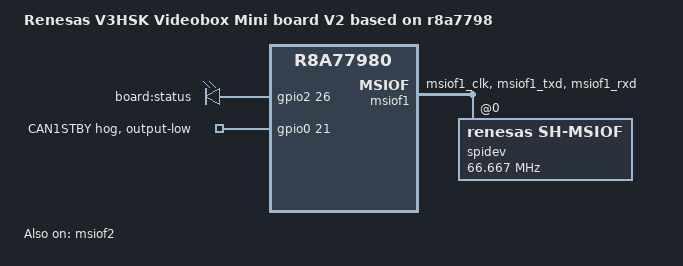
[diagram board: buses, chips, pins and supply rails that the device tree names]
/*
 * Device Tree Source for the V3HSK Videobox Mini board V2 on r8a7798
 *
 * Copyright (C) 2018 Cogent Embedded, Inc.
 *
 * This file is licensed under the terms of the GNU General Public License
 * version 2.  This program is licensed "as is" without any warranty of any
 * kind, whether express or implied.
 */

#include "r8a7798-v3hsk-vbm.dts"

/ {
	model = "Renesas V3HSK Videobox Mini board V2 based on r8a7798";

	leds {
		compatible = "gpio-leds";

		led5 {
			label = "board:status";
			gpios = <&gpio2 26 GPIO_ACTIVE_HIGH>;
			linux,default-trigger = "heartbeat";
		};
	};
};

&gpio0 {
	can1_stby {
		gpio-hog;
		gpios = <21 GPIO_ACTIVE_HIGH>;
		output-low;
		line-name = "CAN1STBY";
	};
};

&pfc {
	msiof1_pins: msiof1 {
		groups = "msiof1_clk", "msiof1_txd", "msiof1_rxd";
		function = "msiof1";
	};

	msiof2_pins: msiof2 {
		groups = "msiof2_clk", "msiof2_sync", "msiof2_txd", "msiof2_rxd";
		function = "msiof2";
	};
};

&scif3 {
	/* pin conflict with msiof2 */
	/* set R240 and remove R241 before enabling */
	status = "disabled";
};

&msiof1 {
	pinctrl-0 = <&msiof1_pins>;
	pinctrl-names = "default";
	cs-gpios = <&gpio3 3 0>;

	status = "okay";
	spidev@0 {
		compatible = "renesas,sh-msiof";
		reg = <0>;
		spi-max-frequency = <66666666>;
	};
};

&msiof2 {
	pinctrl-0 = <&msiof2_pins>;
	pinctrl-names = "default";

	status = "okay";
	slave;
};
